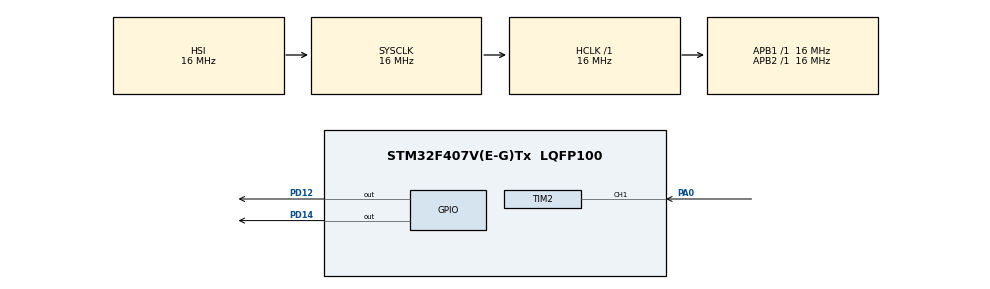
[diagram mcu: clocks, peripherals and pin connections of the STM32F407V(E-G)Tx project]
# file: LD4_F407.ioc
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Mcu.Family=STM32F4
Mcu.Name=STM32F407V(E-G)Tx
Mcu.Package=LQFP100
NVIC.PriorityGroup=NVIC_PRIORITYGROUP_4
NVIC.TIM2_IRQn=true\:0\:0\:false\:false\:true\:true\:true\:true
NVIC.TIM4_IRQn=true\:0\:0\:false\:false\:true\:true\:true\:true
PA0-WKUP.Signal=S_TIM2_CH1_ETR
PA13.Mode=Serial_Wire
PA13.Signal=SYS_JTMS-SWDIO
PA14.Mode=Serial_Wire
PA14.Signal=SYS_JTCK-SWCLK
PD12.Signal=GPIO_Output
PD14.Signal=GPIO_Output
ProjectManager.HeapSize=0x200
ProjectManager.StackSize=0x400
ProjectManager.TargetToolchain=STM32CubeIDE
RCC.AHBFreq_Value=16000000
RCC.APB1Freq_Value=16000000
RCC.APB2Freq_Value=16000000
RCC.CortexFreq_Value=16000000
RCC.HSE_VALUE=25000000
RCC.HSI_VALUE=16000000
RCC.LSE_VALUE=32768
RCC.SYSCLKFreq_VALUE=16000000
RCC.VCOOutputFreq_Value=192000000
SH.S_TIM2_CH1_ETR.0=TIM2_CH1,Input_Capture1_from_TI1
TIM2.Channel-Input_Capture1_from_TI1=TIM_CHANNEL_1
TIM2.ICFilter_CH1=15
TIM2.Period=0xFFFFFFFF
TIM2.Prescaler=16000 - 1
TIM4.Prescaler=16000 - 1
VP_TIM4_VS_ClockSourceINT.Mode=Internal
board=custom

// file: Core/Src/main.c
/* USER CODE BEGIN Header */
/**
  ******************************************************************************
  * @file           : main.c
  * @brief          : Main program body
  ******************************************************************************
  * @attention
  *
  * Copyright (c) 2026 STMicroelectronics.
  * All rights reserved.
  *
  * This software is licensed under terms that can be found in the LICENSE file
  * in the root directory of this software component.
  * If no LICENSE file comes with this software, it is provided AS-IS.
  *
  ******************************************************************************
  */
/* USER CODE END Header */
#include "main.h"

TIM_HandleTypeDef htim2;
TIM_HandleTypeDef htim4;

/* USER CODE BEGIN PV */
volatile uint32_t tim4_ticks = 0;
volatile uint8_t system_state = 0; // 0 = Normalus, 1 = Matuoja, 2 = Rodo rezultatą
volatile uint32_t press_time_ms = 0;
/* USER CODE END PV */

void SystemClock_Config(void);
static void MX_GPIO_Init(void);
static void MX_TIM2_Init(void);
static void MX_TIM4_Init(void);

int main(void)
{

  /* MCU Configuration--------------------------------------------------------*/

  /* Reset of all peripherals, Initializes the Flash interface and the Systick. */
  HAL_Init();

  /* Configure the system clock */
  SystemClock_Config();

  /* Initialize all configured peripherals */
  MX_GPIO_Init();
  MX_TIM2_Init();
  MX_TIM4_Init();
  /* USER CODE BEGIN 2 */
  HAL_TIM_Base_Start_IT(&htim4); // Paleidžiame TIM4 pertrauktis
  HAL_TIM_IC_Start_IT(&htim2, TIM_CHANNEL_1); // Paleidžiame TIM2 Input Capture pertrauktis
  /* USER CODE END 2 */

  /* Infinite loop */
  while (1)
  {

  }
}

void SystemClock_Config(void)
{
  RCC_OscInitTypeDef RCC_OscInitStruct = {0};
  RCC_ClkInitTypeDef RCC_ClkInitStruct = {0};

  /** Configure the main internal regulator output voltage
  */
  __HAL_RCC_PWR_CLK_ENABLE();
  __HAL_PWR_VOLTAGESCALING_CONFIG(PWR_REGULATOR_VOLTAGE_SCALE1);

  /** Initializes the RCC Oscillators according to the specified parameters
  * in the RCC_OscInitTypeDef structure.
  */
  RCC_OscInitStruct.OscillatorType = RCC_OSCILLATORTYPE_HSI;
  RCC_OscInitStruct.HSIState = RCC_HSI_ON;
  RCC_OscInitStruct.HSICalibrationValue = RCC_HSICALIBRATION_DEFAULT;
  RCC_OscInitStruct.PLL.PLLState = RCC_PLL_NONE;
  if (HAL_RCC_OscConfig(&RCC_OscInitStruct) != HAL_OK)
  {
    Error_Handler();
  }

  /** Initializes the CPU, AHB and APB buses clocks
  */
  RCC_ClkInitStruct.ClockType = RCC_CLOCKTYPE_HCLK|RCC_CLOCKTYPE_SYSCLK
                              |RCC_CLOCKTYPE_PCLK1|RCC_CLOCKTYPE_PCLK2;
  RCC_ClkInitStruct.SYSCLKSource = RCC_SYSCLKSOURCE_HSI;
  RCC_ClkInitStruct.AHBCLKDivider = RCC_SYSCLK_DIV1;
  RCC_ClkInitStruct.APB1CLKDivider = RCC_HCLK_DIV1;
  RCC_ClkInitStruct.APB2CLKDivider = RCC_HCLK_DIV1;

  if (HAL_RCC_ClockConfig(&RCC_ClkInitStruct, FLASH_LATENCY_0) != HAL_OK)
  {
    Error_Handler();
  }
}

static void MX_TIM2_Init(void)
{

  TIM_MasterConfigTypeDef sMasterConfig = {0};
  TIM_IC_InitTypeDef sConfigIC = {0};

  htim2.Instance = TIM2;
  htim2.Init.Prescaler = 16000 - 1;
  htim2.Init.CounterMode = TIM_COUNTERMODE_UP;
  htim2.Init.Period = 0xFFFFFFFF;
  htim2.Init.ClockDivision = TIM_CLOCKDIVISION_DIV1;
  htim2.Init.AutoReloadPreload = TIM_AUTORELOAD_PRELOAD_DISABLE;
  if (HAL_TIM_IC_Init(&htim2) != HAL_OK)
  {
    Error_Handler();
  }
  sMasterConfig.MasterOutputTrigger = TIM_TRGO_RESET;
  sMasterConfig.MasterSlaveMode = TIM_MASTERSLAVEMODE_DISABLE;
  if (HAL_TIMEx_MasterConfigSynchronization(&htim2, &sMasterConfig) != HAL_OK)
  {
    Error_Handler();
  }
  sConfigIC.ICPolarity = TIM_INPUTCHANNELPOLARITY_RISING;
  sConfigIC.ICSelection = TIM_ICSELECTION_DIRECTTI;
  sConfigIC.ICPrescaler = TIM_ICPSC_DIV1;
  sConfigIC.ICFilter = 0;
  if (HAL_TIM_IC_ConfigChannel(&htim2, &sConfigIC, TIM_CHANNEL_1) != HAL_OK)
  {
    Error_Handler();
  }

}

static void MX_TIM4_Init(void)
{

  TIM_ClockConfigTypeDef sClockSourceConfig = {0};
  TIM_MasterConfigTypeDef sMasterConfig = {0};

  htim4.Instance = TIM4;
  htim4.Init.Prescaler = 16000 - 1;
  htim4.Init.CounterMode = TIM_COUNTERMODE_UP;
  htim4.Init.Period = 100 - 1;
  htim4.Init.ClockDivision = TIM_CLOCKDIVISION_DIV1;
  htim4.Init.AutoReloadPreload = TIM_AUTORELOAD_PRELOAD_DISABLE;
  if (HAL_TIM_Base_Init(&htim4) != HAL_OK)
  {
    Error_Handler();
  }
  sClockSourceConfig.ClockSource = TIM_CLOCKSOURCE_INTERNAL;
  if (HAL_TIM_ConfigClockSource(&htim4, &sClockSourceConfig) != HAL_OK)
  {
    Error_Handler();
  }
  sMasterConfig.MasterOutputTrigger = TIM_TRGO_RESET;
  sMasterConfig.MasterSlaveMode = TIM_MASTERSLAVEMODE_DISABLE;
  if (HAL_TIMEx_MasterConfigSynchronization(&htim4, &sMasterConfig) != HAL_OK)
  {
    Error_Handler();
  }

}

static void MX_GPIO_Init(void)
{
  GPIO_InitTypeDef GPIO_InitStruct = {0};

  /* GPIO Ports Clock Enable */
  __HAL_RCC_GPIOA_CLK_ENABLE();
  __HAL_RCC_GPIOD_CLK_ENABLE();

  /*Configure GPIO pin Output Level */
  HAL_GPIO_WritePin(GPIOD, GPIO_PIN_12|GPIO_PIN_14, GPIO_PIN_RESET);

  /*Configure GPIO pins : PD12 PD14 */
  GPIO_InitStruct.Pin = GPIO_PIN_12|GPIO_PIN_14;
  GPIO_InitStruct.Mode = GPIO_MODE_OUTPUT_PP;
  GPIO_InitStruct.Pull = GPIO_NOPULL;
  GPIO_InitStruct.Speed = GPIO_SPEED_FREQ_LOW;
  HAL_GPIO_Init(GPIOD, &GPIO_InitStruct);

}

/* USER CODE BEGIN 4 */

// 1. TIM4 Pertrauktis - vyksta kas 100 ms
void HAL_TIM_PeriodElapsedCallback(TIM_HandleTypeDef *htim) {
    if (htim->Instance == TIM4) {
        tim4_ticks++;

        if (system_state == 0) {
            // NORMALUS REŽIMAS
            // PD12 (Žalias) keičia būseną kas 2 sekundes (20 tiksų po 100ms)
            if (tim4_ticks % 20 == 0) {
                HAL_GPIO_TogglePin(GPIOD, GPIO_PIN_12);
            }

            // PD14 (Raudonas) - 4s periodas
            uint32_t period_4s = tim4_ticks % 40;
            if (period_4s < 35) {
                HAL_GPIO_WritePin(GPIOD, GPIO_PIN_14, GPIO_PIN_SET);
            } else {
                HAL_GPIO_WritePin(GPIOD, GPIO_PIN_14, GPIO_PIN_RESET);
            }

        } else if (system_state == 1) {
            // MATAVIMO REŽIMAS
            // Visi LED išjungti, išskyrus PD14 trumpą mirktelėjimą kas 1s
            if (tim4_ticks % 10 == 0) {
                HAL_GPIO_WritePin(GPIOD, GPIO_PIN_14, GPIO_PIN_SET);
            } else if (tim4_ticks % 10 == 1) {
                HAL_GPIO_WritePin(GPIOD, GPIO_PIN_14, GPIO_PIN_RESET);
            }
        }
        // Jei system_state == 2 (Rodo rezultatą), TIM4 nedaro NIEKO.
        // Taip apsaugome rezultato LED nuo perrašymo.
    }
}

// 2. TIM2 Input Capture Pertrauktis - reaguoja į mygtuką (PA0)
void HAL_TIM_IC_CaptureCallback(TIM_HandleTypeDef *htim) {
    if (htim->Instance == TIM2 && htim->Channel == HAL_TIM_ACTIVE_CHANNEL_1) {

        static uint32_t last_press_time = 0;
        if (HAL_GetTick() - last_press_time < 200) return; // Debounce filtras
        last_press_time = HAL_GetTick();

        if (system_state == 0) {
            // 1. Iš normalaus režimo pereiname į matavimą
            system_state = 1;
            __HAL_TIM_SetCounter(htim, 0); // Nunuliname matavimo laikmatį
            tim4_ticks = 0; // Sinchronizuojame mirksėjimą
            HAL_GPIO_WritePin(GPIOD, GPIO_PIN_12 | GPIO_PIN_14, GPIO_PIN_RESET);

        } else if (system_state == 1) {
            // 2. Iš matavimo režimo pereiname į rezultato rodymą
            system_state = 2;
            press_time_ms = HAL_TIM_ReadCapturedValue(htim, TIM_CHANNEL_1);
            float time_sec = press_time_ms / 1000.0f;

            HAL_GPIO_WritePin(GPIOD, GPIO_PIN_12 | GPIO_PIN_14, GPIO_PIN_RESET); // Viską išjungiame

            // Rodome rezultatą
            if (time_sec > 0 && time_sec <= 4.0f) {
                HAL_GPIO_WritePin(GPIOD, GPIO_PIN_12, GPIO_PIN_SET); // Žalias
            } else if (time_sec > 4.0f && time_sec <= 8.0f) {
                HAL_GPIO_WritePin(GPIOD, GPIO_PIN_14, GPIO_PIN_SET); // Raudonas
            } else if (time_sec > 8.0f && time_sec <= 12.0f) {
                HAL_GPIO_WritePin(GPIOD, GPIO_PIN_12 | GPIO_PIN_14, GPIO_PIN_SET); // Abu
            }

        } else if (system_state == 2) {
            // 3. Po rezultato rodymo - mygtuko paspaudimas grąžina į normalų režimą
            system_state = 0;
            tim4_ticks = 0; // Iš naujo pradedame gražų mirksėjimo ciklą
        }
    }
}
/* USER CODE END 4 */

void Error_Handler(void)
{
  __disable_irq();
  while (1)
  {
  }
}
